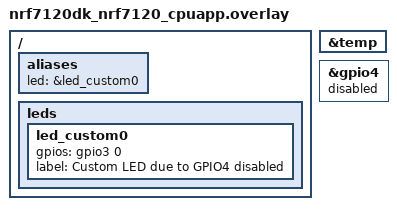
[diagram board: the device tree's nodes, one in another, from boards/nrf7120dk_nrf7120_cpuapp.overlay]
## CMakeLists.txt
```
#
# Copyright (c) 2024 Nordic Semiconductor ASA
#
# SPDX-License-Identifier: LicenseRef-Nordic-5-Clause
#

cmake_minimum_required(VERSION 3.20.0)

find_package(Zephyr REQUIRED HINTS $ENV{ZEPHYR_BASE})

project(temperature_sensor)

target_sources(app PRIVATE ./../common/main.c)
target_sources(app PRIVATE src/main.c)
```

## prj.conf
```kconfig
CONFIG_SENSOR=y

CONFIG_PM=y
CONFIG_POWEROFF=y

CONFIG_ASSERT=y

CONFIG_CONSOLE=n
CONFIG_UART_CONSOLE=n
CONFIG_SERIAL=n
CONFIG_BOOT_BANNER=n
CONFIG_NCS_BOOT_BANNER=n
```

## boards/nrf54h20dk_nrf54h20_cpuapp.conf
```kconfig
CONFIG_PM_S2RAM=y

CONFIG_NRFS=y

CONFIG_SOC_NRF54H20_CPURAD_ENABLE=y
```

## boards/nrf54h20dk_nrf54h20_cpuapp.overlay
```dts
/ {
	aliases {
		led = &led0;
		/delete-property/ led1;
	};
};

/delete-node/ &led1;

temp_sensor: &temp_nrfs {
	status = "okay";
};

&gpio6 {
	status = "disabled";
};

&exmif {
	status = "disabled";
};
```

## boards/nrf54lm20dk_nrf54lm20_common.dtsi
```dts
/ {
	aliases {
		led = &led0;
	};
};

temp_sensor: &temp {
	status = "okay";
};
```

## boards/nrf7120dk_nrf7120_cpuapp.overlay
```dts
/ {
	aliases {
		led = &led_custom0;
	};

	leds {
		led_custom0: led_custom0 {
			gpios = <&gpio3 0 GPIO_ACTIVE_HIGH>;
			label = "Custom LED due to GPIO4 disabled";
		};
	};
};

temp_sensor: &temp {
	status = "okay";
};

&gpio4 {
	status = "disabled";
};
```

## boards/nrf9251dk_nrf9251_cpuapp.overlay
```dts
/ {
	aliases {
		led = &led0;
	};
};

temp_sensor: &temp_nrfs {
	status = "okay";
};
```

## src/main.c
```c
/*
 * Copyright (c) 2024, Nordic Semiconductor ASA
 *
 * SPDX-License-Identifier: LicenseRef-Nordic-5-Clause
 */
#include <zephyr/device.h>
#include <zephyr/drivers/sensor.h>
#include <zephyr/kernel.h>

static const struct device *temp_dev = DEVICE_DT_GET(DT_NODELABEL(temp_sensor));

static bool suspend_req;

bool self_suspend_req(void)
{
	suspend_req = true;
	return true;
}

void thread_definition(void)
{
	int rc;
	int32_t temp_val;
	struct sensor_value val;

	while (1) {
		if (suspend_req) {
			suspend_req = false;
			k_thread_suspend(k_current_get());
		}

		rc = sensor_sample_fetch_chan(temp_dev, SENSOR_CHAN_DIE_TEMP);
		__ASSERT(rc == 0, "Cannot fetch chan sample: %d.", rc);

		rc = sensor_channel_get(temp_dev, SENSOR_CHAN_DIE_TEMP, &val);
		__ASSERT(rc == 0, "Cannot read from channel %d: %d.",
			   SENSOR_CHAN_DIE_TEMP, rc);

		temp_val = (val.val1 * 100) + (val.val2 / 10000);
		printk("Temperature: %d.%02u\n",
			temp_val/100, abs(temp_val) % 100);

		__ASSERT(val.val1 > 10, "Temperature to low (laboratory conditions)");
		__ASSERT(val.val1 < 35, "Temperature too high (laboratory conditions)");

		k_sleep(K_MSEC(20));
	};
};
```
